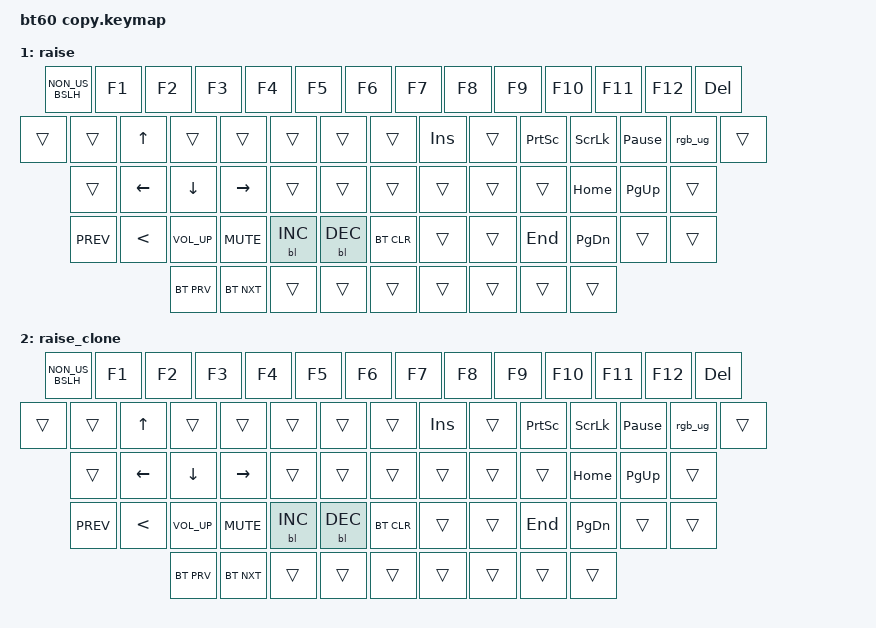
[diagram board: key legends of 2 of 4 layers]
#include <behaviors.dtsi>
#include <dt-bindings/zmk/keys.h>
#include <dt-bindings/zmk/bt.h>
#include <dt-bindings/zmk/rgb.h>
#include <dt-bindings/zmk/backlight.h>

/ {

	  conditional_layers {
            compatible = "zmk,conditional-layers";
            config_from_default {
                if-layers = <1 2>;
                then-layer = <3>;
			};
        };

	keymap {
		compatible = "zmk,keymap";

		default_layer {
				// ------------------------------------------------------------------------------------------
				// |  `  |  1  |  2  |  3  |  4  |  5  |  6  |  7  |  8  |  9  |  0  |  -  |  =  |   BKSP
				// | TAB  |  Q  |  W  |  E  |  R  |  T  |  Y  |  U  |  I  |  O  |  P  |  [  |  ]  |   |
				// | CAPS  |  A  |  S  |  D  |  F  |  G  |  H  |  J  |  K  |  L  |  ;  |  '  |     ENTER
				// |  SHIFT    |  Z  |  X  |  C  |  V  |  B  |  N  |  M  |  ,  |  .  |   SHIFT | UP | ?
				// |  CTL  |  WIN  |  ALT  |            SPACE               | ALT | 1 | LEFT | DOWN |RIGHT
				// ------------------------------------------------------------------------------------------
			bindings = <

				&kp ESC &kp N1 &kp N2 &kp N3 &kp N4 &kp N5 &kp N6 &kp N7 &kp  N8   &kp  N9 &kp  N0  &kp MINUS &kp EQUAL &kp BSPC
				&kp TAB  &kp Q  &kp W  &kp E  &kp R  &kp T  &kp Y  &kp U  &kp  I    &kp  O  &kp  P   &kp LBKT &kp RBKT   &kp BSLH
				&mo 2  &kp A  &kp S  &kp D  &kp F  &kp G  &kp H  &kp J  &kp  K    &kp  L  &kp SEMI &kp SQT            &kp RET
				&kp LSHFT  &kp Z  &kp X  &kp C  &kp V  &kp B  &kp N  &kp M  &kp COMMA &kp DOT &kp RSHFT  &kp UP  &kp FSLH
				&kp LCTRL &kp LGUI &kp LALT            &kp SPACE                          &kp RALT  &mo 1 &kp LEFT  &kp DOWN  &kp RIGHT
			>;
			sensor-bindings = <&inc_dec_kp C_VOL_UP C_VOL_DN>;
		};
		raise {
			bindings = <
				&kp NON_US_BSLH &kp F1 &kp F2 &kp F3 &kp F4 &kp F5 &kp F6 &kp F7 &kp F8 &kp F9 &kp F10 &kp F11 &kp F12 &kp DEL
				&trans &trans &kp UP &trans &trans &trans &trans &trans &kp INS &trans &kp PSCRN &kp SLCK &kp PAUSE_BREAK &rgb_ug &trans
				&trans    &kp LEFT &kp DOWN &kp RIGHT &trans &trans &trans &trans &trans &trans &kp HOME  &kp PG_UP   &trans
				&kp C_PREV &kp LESS_THAN &kp C_VOL_UP &kp C_MUTE &bl BL_INC &bl BL_DEC &bt BT_CLR &trans &trans &kp END &kp PG_DN  &trans  &trans 
				&bt BT_PRV &bt BT_NXT  &trans              &trans                            &trans   &trans  &trans &trans  &trans 
			>;
			sensor-bindings = <&inc_dec_kp C_VOL_UP C_VOL_DN>;
		};
		raise_clone {
			bindings = <
				&kp NON_US_BSLH &kp F1 &kp F2 &kp F3 &kp F4 &kp F5 &kp F6 &kp F7 &kp F8 &kp F9 &kp F10 &kp F11 &kp F12 &kp DEL
				&trans &trans &kp UP &trans &trans &trans &trans &trans &kp INS &trans &kp PSCRN &kp SLCK &kp PAUSE_BREAK &rgb_ug &trans
				&trans    &kp LEFT &kp DOWN &kp RIGHT &trans &trans &trans &trans &trans &trans &kp HOME  &kp PG_UP   &trans
				&kp C_PREV &kp LESS_THAN &kp C_VOL_UP &kp C_MUTE &bl BL_INC &bl BL_DEC &bt BT_CLR &trans &trans &kp END &kp PG_DN  &trans  &trans 
				&bt BT_PRV &bt BT_NXT  &trans              &trans                            &trans   &trans  &trans &trans  &trans 
			>;
			sensor-bindings = <&inc_dec_kp C_VOL_UP C_VOL_DN>;
		};
		setup {
			bindings = <
				&bt BT_CLR &bt BT_SEL 0 &bt BT_SEL 1 &bt BT_SEL 2 &kp F4 &kp F5 &kp F6 &kp F7 &kp F8 &kp F9 &kp F10 &kp F11 &kp F12 &kp DEL
				&trans &trans &kp UP &reset &trans &trans &trans &trans &kp INS &trans &kp PSCRN &kp SLCK &kp PAUSE_BREAK &rgb_ug RGB_TOG
				&mo 2    &kp LEFT &kp DOWN &kp RIGHT &bootloader &trans &trans &trans &trans &trans &kp HOME  &kp PG_UP   &trans
				&kp C_PREV &kp C_VOL_DN &kp C_VOL_UP &kp C_MUTE &bt BT_PRV &bt BT_CLR &bt BT_NXT &trans &trans &kp END &kp PG_DN  &bl BL_INC &reset
				&bt BT_PRV &bt BT_NXT  &trans              &trans                            &trans   &mo 2  &trans &bl BL_DEC  &trans 
			>;
			sensor-bindings = <&inc_dec_kp C_VOL_UP C_VOL_DN>;
		};
	};
};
